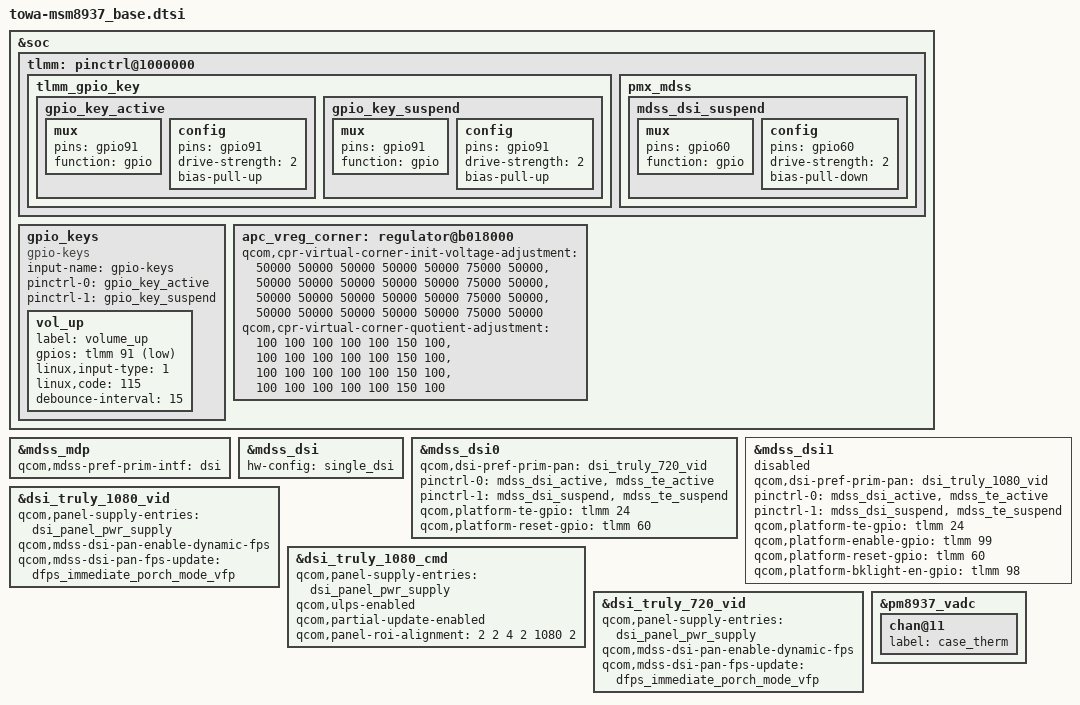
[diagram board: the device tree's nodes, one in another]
/*
 * Copyright (c) 2015-2016, The Linux Foundation. All rights reserved.
 *
 * This program is free software; you can redistribute it and/or modify
 * it under the terms of the GNU General Public License version 2 and
 * only version 2 as published by the Free Software Foundation.
 *
 * This program is distributed in the hope that it will be useful,
 * but WITHOUT ANY WARRANTY; without even the implied warranty of
 * MERCHANTABILITY or FITNESS FOR A PARTICULAR PURPOSE.  See the
 * GNU General Public License for more details.
 */

#include "towa-common.dtsi"
#include "msm8937-mdss-panels.dtsi"

&soc {
	tlmm: pinctrl@1000000 {
		tlmm_gpio_key {
			gpio_key_active: gpio_key_active {
				mux {
					pins = "gpio91";
					function = "gpio";
				};

				config {
					pins = "gpio91";
					drive-strength = <2>;
					bias-pull-up;
				};
			};

			gpio_key_suspend: gpio_key_suspend {
				mux {
					pins = "gpio91";
					function = "gpio";
				};

				config {
					pins = "gpio91";
					drive-strength = <2>;
					bias-pull-up;
				};
			};
		};

		pmx_mdss: pmx_mdss {
			mdss_dsi_suspend: mdss_dsi_suspend {
				mux {
					pins = "gpio60";
					function = "gpio";
				};

				config {
					pins = "gpio60";
					drive-strength = <2>; /* 2 mA */
					bias-pull-down; /* pull down */
					/delete-property/ input-enable;
				};
			};
		};

	};
	gpio_keys {
		compatible = "gpio-keys";
		input-name = "gpio-keys";
		pinctrl-names = "tlmm_gpio_key_active","tlmm_gpio_key_suspend";
		pinctrl-0 = <&gpio_key_active>;
		pinctrl-1 = <&gpio_key_suspend>;

		vol_up {
			label = "volume_up";
			gpios = <&tlmm 91 0x1>;
			linux,input-type = <1>;
			linux,code = <115>;
			debounce-interval = <15>;
		};
	};
	apc_vreg_corner: regulator@b018000 {
		qcom,cpr-virtual-corner-init-voltage-adjustment =
				<50000 50000 50000 50000 50000 75000 50000>,
				<50000 50000 50000 50000 50000 75000 50000>,
				<50000 50000 50000 50000 50000 75000 50000>,
				<50000 50000 50000 50000 50000 75000 50000>;

		qcom,cpr-virtual-corner-quotient-adjustment =
				<100 100 100 100 100 150 100>,
				<100 100 100 100 100 150 100>,
				<100 100 100 100 100 150 100>,
				<100 100 100 100 100 150 100>;	
	};
};

&mdss_mdp {
	qcom,mdss-pref-prim-intf = "dsi";
};

&mdss_dsi {
	hw-config = "single_dsi";
};

&mdss_dsi0 {
	qcom,dsi-pref-prim-pan = <&dsi_truly_720_vid>;
	pinctrl-names = "mdss_default", "mdss_sleep";
	pinctrl-0 = <&mdss_dsi_active &mdss_te_active>;
	pinctrl-1 = <&mdss_dsi_suspend &mdss_te_suspend>;

	qcom,platform-te-gpio = <&tlmm 24 0>;
	//qcom,platform-enable-gpio = <&tlmm 99 0>;
	qcom,platform-reset-gpio = <&tlmm 60 0>;
	//qcom,platform-bklight-en-gpio = <&tlmm 98 0>;
};

&mdss_dsi1 {
	status = "disabled";
	qcom,dsi-pref-prim-pan = <&dsi_truly_1080_vid>;
	pinctrl-names = "mdss_default", "mdss_sleep";
	pinctrl-0 = <&mdss_dsi_active &mdss_te_active>;
	pinctrl-1 = <&mdss_dsi_suspend &mdss_te_suspend>;

	qcom,platform-te-gpio = <&tlmm 24 0>;
	qcom,platform-enable-gpio = <&tlmm 99 0>;
	qcom,platform-reset-gpio = <&tlmm 60 0>;
	qcom,platform-bklight-en-gpio = <&tlmm 98 0>;
};

&dsi_truly_1080_vid {
	qcom,panel-supply-entries = <&dsi_panel_pwr_supply>;
	qcom,mdss-dsi-pan-enable-dynamic-fps;
	qcom,mdss-dsi-pan-fps-update = "dfps_immediate_porch_mode_vfp";
};

&dsi_truly_1080_cmd {
	qcom,panel-supply-entries = <&dsi_panel_pwr_supply>;
	qcom,ulps-enabled;
	qcom,partial-update-enabled;
	qcom,panel-roi-alignment = <2 2 4 2 1080 2>;
};

&dsi_truly_720_vid {
	qcom,panel-supply-entries = <&dsi_panel_pwr_supply>;
	qcom,mdss-dsi-pan-enable-dynamic-fps;
	qcom,mdss-dsi-pan-fps-update = "dfps_immediate_porch_mode_vfp";
};

&pm8937_vadc {
	chan@11 {
		label = "case_therm";
	};
};
